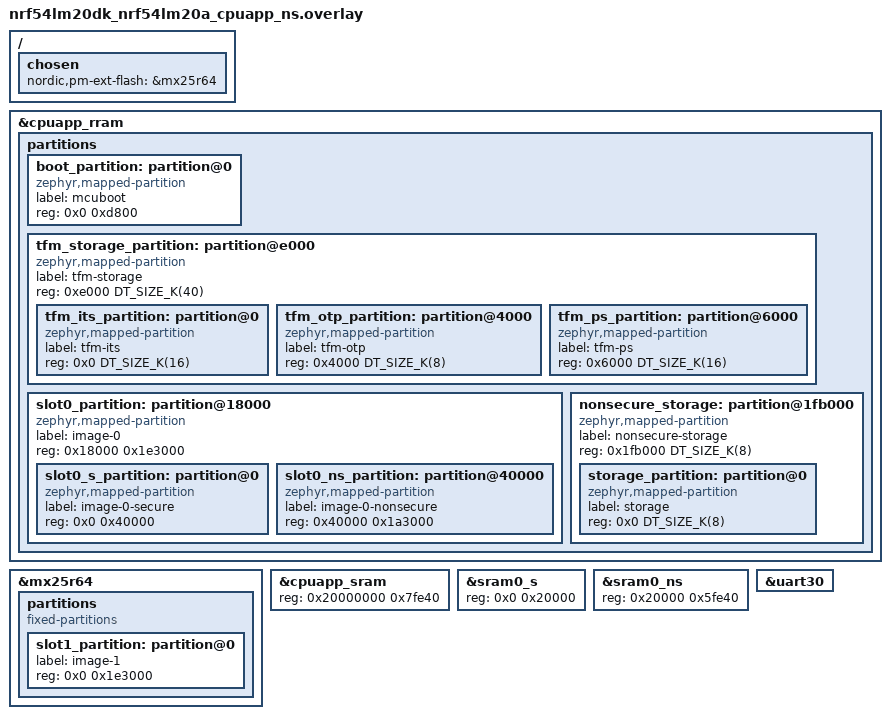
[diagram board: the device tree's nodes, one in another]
/*
 * Copyright (c) 2026 Nordic Semiconductor ASA
 *
 * SPDX-License-Identifier: LicenseRef-Nordic-5-Clause
 */

/ {
	/* Configure partition manager to use mx25r64 as the external flash */
	chosen {
		nordic,pm-ext-flash = &mx25r64;
	};
};

/delete-node/ &slot0_s_partition;
/delete-node/ &tfm_ps_partition;
/delete-node/ &tfm_its_partition;
/delete-node/ &tfm_otp_partition;
/delete-node/ &slot0_ns_partition;
/delete-node/ &storage_partition;

&cpuapp_rram {
	partitions {
		boot_partition: partition@0 {
			compatible = "zephyr,mapped-partition";
			label = "mcuboot";
			reg = <0x0 0xd800>;
		};

		tfm_storage_partition: partition@e000 {
			compatible = "zephyr,mapped-partition";
			label = "tfm-storage";
			reg = <0xe000 DT_SIZE_K(40)>;
			ranges = <0x0 0xe000 DT_SIZE_K(40)>;
			#address-cells = <1>;
			#size-cells = <1>;

			tfm_its_partition: partition@0 {
				compatible = "zephyr,mapped-partition";
				label = "tfm-its";
				reg = <0x0 DT_SIZE_K(16)>;
			};

			tfm_otp_partition: partition@4000 {
				compatible = "zephyr,mapped-partition";
				label = "tfm-otp";
				reg = <0x4000 DT_SIZE_K(8)>;
			};

			tfm_ps_partition: partition@6000 {
				compatible = "zephyr,mapped-partition";
				label = "tfm-ps";
				reg = <0x6000 DT_SIZE_K(16)>;
			};
		};

		slot0_partition: partition@18000 {
			compatible = "zephyr,mapped-partition";
			label = "image-0";
			reg = <0x18000 0x1e3000>;
			ranges = <0x0 0x18000 0x1e3000>;
			#address-cells = <1>;
			#size-cells = <1>;

			slot0_s_partition: partition@0 {
				compatible = "zephyr,mapped-partition";
				label = "image-0-secure";
				reg = <0x0 0x40000>;
			};

			slot0_ns_partition: partition@40000 {
				compatible = "zephyr,mapped-partition";
				label = "image-0-nonsecure";
				reg = <0x40000 0x1a3000>;
			};
		};

		nonsecure_storage: partition@1fb000 {
			compatible = "zephyr,mapped-partition";
			label = "nonsecure-storage";
			reg = <0x1fb000 DT_SIZE_K(8)>;
			ranges = <0x0 0x1fb000 DT_SIZE_K(8)>;
			#address-cells = <1>;
			#size-cells = <1>;

			storage_partition: partition@0 {
				compatible = "zephyr,mapped-partition";
				label = "storage";
				reg = <0x0 DT_SIZE_K(8)>;
			};
		};
	};
};

&mx25r64 {
	status = "okay";

	partitions {
		compatible = "fixed-partitions";
		#address-cells = <1>;
		#size-cells = <1>;

		slot1_partition: partition@0 {
			label = "image-1";
			reg = <0x0 0x1e3000>;
		};
	};
};

/*
 * CPUAPP SRAM TrustZone split: TF-M uses the first 128 KiB (&sram0_s, reg 0x20000); the NS
 * workload uses the remainder (&sram0_ns). These sizes must match the TF-M platform RAM
 * layout for nRF54LM20.
 */
&cpuapp_sram {
	reg = <0x20000000 0x7fe40>;
	ranges = <0x0 0x20000000 0x7fe40>;
};

&sram0_s {
	reg = <0x0 0x20000>;
	ranges = <0x0 0x0 0x20000>;
};

&sram0_ns {
	reg = <0x20000 0x5fe40>;
	ranges = <0x0 0x20000 0x5fe40>;
};

/*
 * Board NS DTS keeps &uart30 disabled for the default TF-M UARTE30 logging case.
 * With CONFIG_TFM_LOG_LEVEL_SILENCE=y TF-M does not use that UART; re-enable UARTE30 for NS.
 */
&uart30 {
	status = "okay";
};
